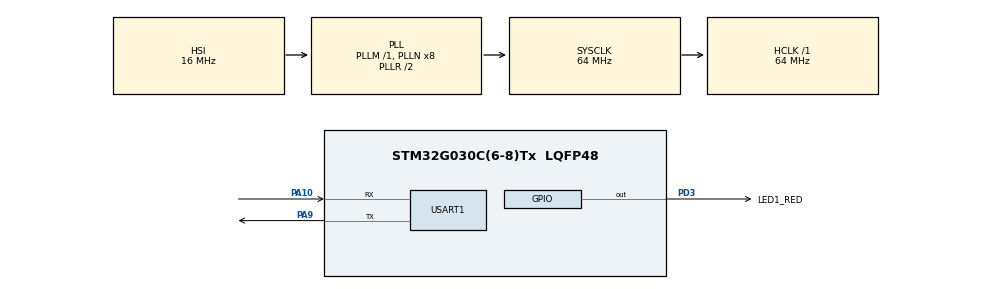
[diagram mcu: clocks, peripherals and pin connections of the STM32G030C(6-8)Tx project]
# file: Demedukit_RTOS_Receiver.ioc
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FREERTOS.Queues01=DataQueue,64,uint8_t,0,Dynamic,NULL,NULL
FREERTOS.Tasks01=defaultTask,24,128,StartDefaultTask,Default,NULL,Dynamic,NULL,NULL;ReceiverTask,24,128,StartReceiverTask,Default,NULL,Dynamic,NULL,NULL
FREERTOS.configTOTAL_HEAP_SIZE=3000
FREERTOS.configUSE_NEWLIB_REENTRANT=1
Mcu.Family=STM32G0
Mcu.Name=STM32G030C(6-8)Tx
Mcu.Package=LQFP48
NVIC.TIM3_IRQn=true\:3\:0\:false\:false\:true\:false\:false\:true\:true
NVIC.TimeBase=TIM3_IRQn
NVIC.TimeBaseIP=TIM3
NVIC.USART1_IRQn=true\:3\:0\:true\:false\:true\:true\:true\:true\:true
PA10.Mode=Asynchronous
PA10.Signal=USART1_RX
PA9.Mode=Asynchronous
PA9.Signal=USART1_TX
PD3.GPIO_Label=LED1_RED
PD3.Signal=GPIO_Output
PF0-OSC_IN\ (PF0).Mode=HSE-External-Oscillator
PF0-OSC_IN\ (PF0).Signal=RCC_OSC_IN
PF1-OSC_OUT\ (PF1).Mode=HSE-External-Oscillator
PF1-OSC_OUT\ (PF1).Signal=RCC_OSC_OUT
ProjectManager.HeapSize=0x0
ProjectManager.StackSize=0x200
ProjectManager.TargetToolchain=STM32CubeIDE
RCC.ADCFreq_Value=64000000
RCC.AHBFreq_Value=64000000
RCC.CortexFreq_Value=64000000
RCC.EXTERNAL_CLOCK_VALUE=12288000
RCC.HCLKFreq_Value=64000000
RCC.HSE_VALUE=8000000
RCC.HSI_VALUE=16000000
RCC.LSE_VALUE=32768
RCC.SYSCLKFreq_VALUE=64000000
RCC.SYSCLKSource=RCC_SYSCLKSOURCE_PLLCLK
RCC.VCOOutputFreq_Value=128000000
USART1.VirtualMode-Asynchronous=VM_ASYNC
VP_FREERTOS_VS_CMSIS_V2.Mode=CMSIS_V2
VP_SYS_VS_tim3.Mode=TIM3
board=custom

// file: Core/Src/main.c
/* USER CODE BEGIN Header */
/**
  ******************************************************************************
  * @file           : main.c
  * @brief          : Main program body
  ******************************************************************************
  * @attention
  *
  * Copyright (c) 2026 STMicroelectronics.
  * All rights reserved.
  *
  * This software is licensed under terms that can be found in the LICENSE file
  * in the root directory of this software component.
  * If no LICENSE file comes with this software, it is provided AS-IS.
  *
  ******************************************************************************
  */
/* USER CODE END Header */
#include "main.h"
#include "cmsis_os.h"

UART_HandleTypeDef huart1;

/* Definitions for defaultTask */
osThreadId_t defaultTaskHandle;
const osThreadAttr_t defaultTask_attributes = {
  .name = "defaultTask",
  .priority = (osPriority_t) osPriorityNormal,
  .stack_size = 128 * 4
};
/* Definitions for ReceiverTask */
osThreadId_t ReceiverTaskHandle;
const osThreadAttr_t ReceiverTask_attributes = {
  .name = "ReceiverTask",
  .priority = (osPriority_t) osPriorityNormal,
  .stack_size = 128 * 4
};
/* Definitions for DataQueue */
osMessageQueueId_t DataQueueHandle;
const osMessageQueueAttr_t DataQueue_attributes = {
  .name = "DataQueue"
};
/* USER CODE BEGIN PV */
uint8_t rx_data; // UART'tan gelen tek baytlık veri
extern osMessageQueueId_t DataQueueHandle; // MX tarafından oluşturulan kuyruk ID'si

/* USER CODE END PV */

void SystemClock_Config(void);
static void MX_GPIO_Init(void);
static void MX_USART1_UART_Init(void);
void StartDefaultTask(void *argument);
void StartReceiverTask(void *argument);

int main(void)
{

  /* MCU Configuration--------------------------------------------------------*/

  /* Reset of all peripherals, Initializes the Flash interface and the Systick. */
  HAL_Init();

  /* Configure the system clock */
  SystemClock_Config();

  /* Initialize all configured peripherals */
  MX_GPIO_Init();
  MX_USART1_UART_Init();
  /* USER CODE BEGIN 2 */
  HAL_UART_Receive_IT(&huart1, &rx_data, 1); // UART1'den 1 bayt veri beklemeye başla

  /* USER CODE END 2 */

  /* Init scheduler */
  osKernelInitialize();

  /* Create the queue(s) */
  /* creation of DataQueue */
  DataQueueHandle = osMessageQueueNew (64, sizeof(uint8_t), &DataQueue_attributes);

  /* Create the thread(s) */
  /* creation of defaultTask */
  defaultTaskHandle = osThreadNew(StartDefaultTask, NULL, &defaultTask_attributes);

  /* creation of ReceiverTask */
  ReceiverTaskHandle = osThreadNew(StartReceiverTask, NULL, &ReceiverTask_attributes);

  /* Start scheduler */
  osKernelStart();

  /* We should never get here as control is now taken by the scheduler */

  /* Infinite loop */
  while (1)
  {

  }
}

void SystemClock_Config(void)
{
  RCC_OscInitTypeDef RCC_OscInitStruct = {0};
  RCC_ClkInitTypeDef RCC_ClkInitStruct = {0};

  /** Configure the main internal regulator output voltage
  */
  HAL_PWREx_ControlVoltageScaling(PWR_REGULATOR_VOLTAGE_SCALE1);

  /** Initializes the RCC Oscillators according to the specified parameters
  * in the RCC_OscInitTypeDef structure.
  */
  RCC_OscInitStruct.OscillatorType = RCC_OSCILLATORTYPE_HSI;
  RCC_OscInitStruct.HSIState = RCC_HSI_ON;
  RCC_OscInitStruct.HSIDiv = RCC_HSI_DIV1;
  RCC_OscInitStruct.HSICalibrationValue = RCC_HSICALIBRATION_DEFAULT;
  RCC_OscInitStruct.PLL.PLLState = RCC_PLL_ON;
  RCC_OscInitStruct.PLL.PLLSource = RCC_PLLSOURCE_HSI;
  RCC_OscInitStruct.PLL.PLLM = RCC_PLLM_DIV1;
  RCC_OscInitStruct.PLL.PLLN = 8;
  RCC_OscInitStruct.PLL.PLLP = RCC_PLLP_DIV2;
  RCC_OscInitStruct.PLL.PLLR = RCC_PLLR_DIV2;
  if (HAL_RCC_OscConfig(&RCC_OscInitStruct) != HAL_OK)
  {
    Error_Handler();
  }

  /** Initializes the CPU, AHB and APB buses clocks
  */
  RCC_ClkInitStruct.ClockType = RCC_CLOCKTYPE_HCLK|RCC_CLOCKTYPE_SYSCLK
                              |RCC_CLOCKTYPE_PCLK1;
  RCC_ClkInitStruct.SYSCLKSource = RCC_SYSCLKSOURCE_PLLCLK;
  RCC_ClkInitStruct.AHBCLKDivider = RCC_SYSCLK_DIV1;
  RCC_ClkInitStruct.APB1CLKDivider = RCC_HCLK_DIV1;

  if (HAL_RCC_ClockConfig(&RCC_ClkInitStruct, FLASH_LATENCY_2) != HAL_OK)
  {
    Error_Handler();
  }
}

static void MX_USART1_UART_Init(void)
{

  huart1.Instance = USART1;
  huart1.Init.BaudRate = 115200;
  huart1.Init.WordLength = UART_WORDLENGTH_8B;
  huart1.Init.StopBits = UART_STOPBITS_1;
  huart1.Init.Parity = UART_PARITY_NONE;
  huart1.Init.Mode = UART_MODE_TX_RX;
  huart1.Init.HwFlowCtl = UART_HWCONTROL_NONE;
  huart1.Init.OverSampling = UART_OVERSAMPLING_16;
  huart1.Init.OneBitSampling = UART_ONE_BIT_SAMPLE_DISABLE;
  huart1.Init.ClockPrescaler = UART_PRESCALER_DIV1;
  huart1.AdvancedInit.AdvFeatureInit = UART_ADVFEATURE_NO_INIT;
  if (HAL_UART_Init(&huart1) != HAL_OK)
  {
    Error_Handler();
  }
  if (HAL_UARTEx_SetTxFifoThreshold(&huart1, UART_TXFIFO_THRESHOLD_1_8) != HAL_OK)
  {
    Error_Handler();
  }
  if (HAL_UARTEx_SetRxFifoThreshold(&huart1, UART_RXFIFO_THRESHOLD_1_8) != HAL_OK)
  {
    Error_Handler();
  }
  if (HAL_UARTEx_DisableFifoMode(&huart1) != HAL_OK)
  {
    Error_Handler();
  }

}

static void MX_GPIO_Init(void)
{
  GPIO_InitTypeDef GPIO_InitStruct = {0};

  /* GPIO Ports Clock Enable */
  __HAL_RCC_GPIOF_CLK_ENABLE();
  __HAL_RCC_GPIOA_CLK_ENABLE();
  __HAL_RCC_GPIOD_CLK_ENABLE();

  /*Configure GPIO pin Output Level */
  HAL_GPIO_WritePin(LED1_RED_GPIO_Port, LED1_RED_Pin, GPIO_PIN_RESET);

  /*Configure GPIO pin : LED1_RED_Pin */
  GPIO_InitStruct.Pin = LED1_RED_Pin;
  GPIO_InitStruct.Mode = GPIO_MODE_OUTPUT_PP;
  GPIO_InitStruct.Pull = GPIO_NOPULL;
  GPIO_InitStruct.Speed = GPIO_SPEED_FREQ_LOW;
  HAL_GPIO_Init(LED1_RED_GPIO_Port, &GPIO_InitStruct);

}

/* USER CODE BEGIN 4 */

void HAL_UART_RxCpltCallback(UART_HandleTypeDef *huart)
{
  if(huart->Instance == USART1)
  {
    // Gelen baytı kuyruğa (Queue) gönder (ISR güvenli versiyonu)
    osMessageQueuePut(DataQueueHandle, &rx_data, 0, 0);

    // Bir sonraki bayt için kesmeyi tekrar aktif et
    HAL_UART_Receive_IT(&huart1, &rx_data, 1);
  }
}

/* USER CODE END 4 */

void StartDefaultTask(void *argument)
{
  for(;;)
  {
    osDelay(1);
  }
}

void StartReceiverTask(void *argument)
{
  /* USER CODE BEGIN StartReceiverTask */
  uint8_t received_byte;
  /* Infinite loop */
  for(;;)
  {
   // Kuyrukta veri var mı diye bekle (osWaitForever)
    if (osMessageQueueGet(DataQueueHandle, &received_byte, NULL, osWaitForever) == osOK)
    {
     // Eğer gelen veri varsa PD3 (LED1_RED) yak/sön yap
     HAL_GPIO_TogglePin(LED1_RED_GPIO_Port, LED1_RED_Pin);
     osDelay(50);
    }
  }
  /* USER CODE END StartReceiverTask */
}

void HAL_TIM_PeriodElapsedCallback(TIM_HandleTypeDef *htim)
{
  if (htim->Instance == TIM3)
  {
    HAL_IncTick();
  }
}

void Error_Handler(void)
{
  __disable_irq();
  while (1)
  {
  }
}
